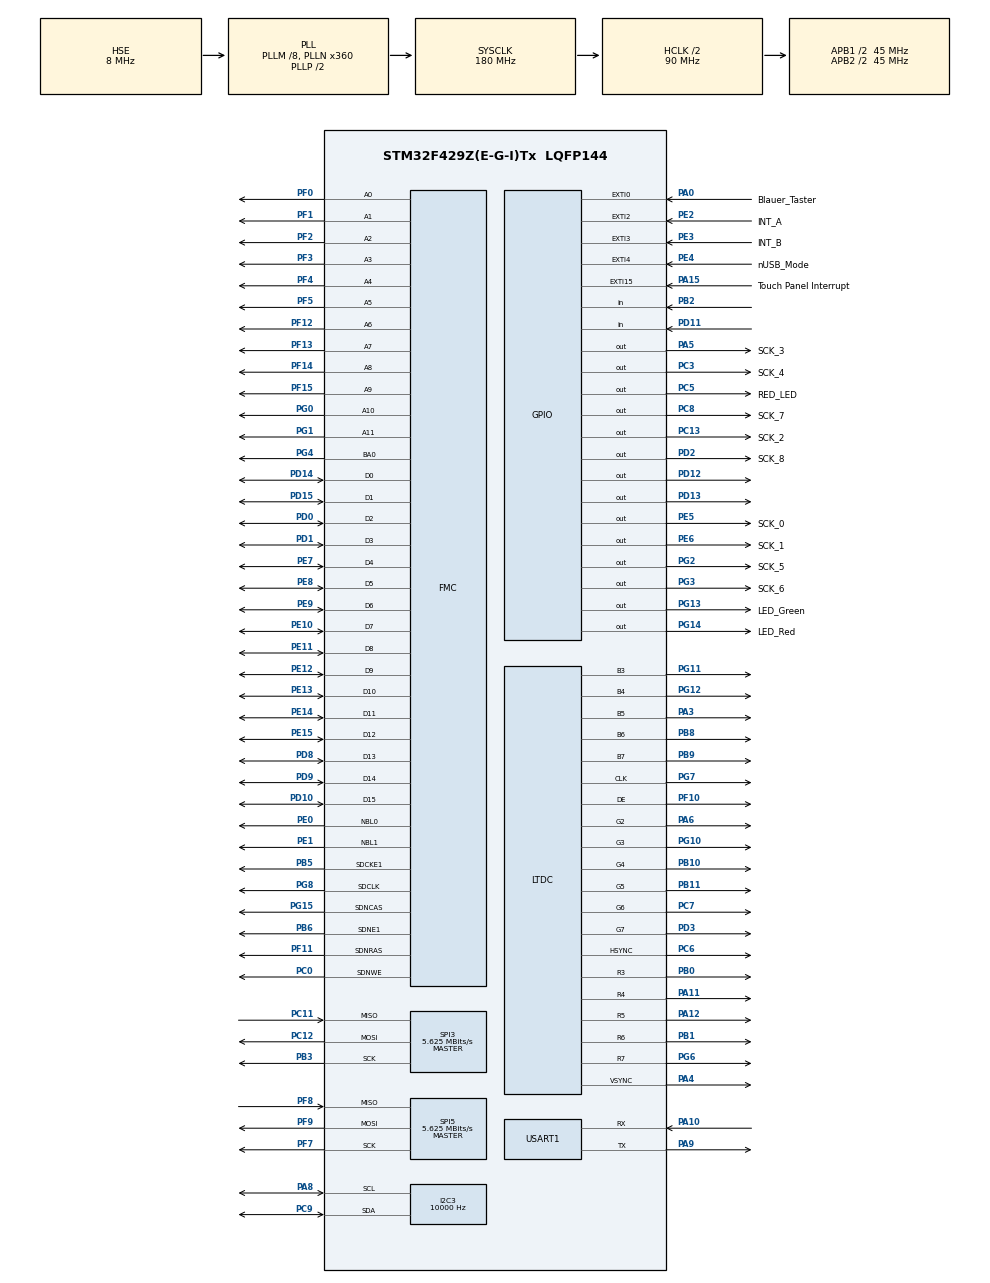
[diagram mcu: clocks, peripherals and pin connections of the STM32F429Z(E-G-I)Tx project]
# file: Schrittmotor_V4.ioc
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DMA2D.AlphaModeForeground=DMA2D_COMBINE_ALPHA
DMA2D.Mode=DMA2D_M2M
Dma.MEMTOMEM.2.Direction=DMA_MEMORY_TO_MEMORY
Dma.MEMTOMEM.2.FIFOMode=DMA_FIFOMODE_ENABLE
Dma.MEMTOMEM.2.FIFOThreshold=DMA_FIFO_THRESHOLD_FULL
Dma.MEMTOMEM.2.Instance=DMA2_Stream0
Dma.MEMTOMEM.2.MemBurst=DMA_MBURST_SINGLE
Dma.MEMTOMEM.2.MemDataAlignment=DMA_MDATAALIGN_BYTE
Dma.MEMTOMEM.2.MemInc=DMA_MINC_ENABLE
Dma.MEMTOMEM.2.Mode=DMA_NORMAL
Dma.MEMTOMEM.2.PeriphBurst=DMA_PBURST_SINGLE
Dma.MEMTOMEM.2.PeriphDataAlignment=DMA_PDATAALIGN_BYTE
Dma.MEMTOMEM.2.PeriphInc=DMA_PINC_ENABLE
Dma.MEMTOMEM.2.Priority=DMA_PRIORITY_LOW
Dma.Request0=USART1_RX
Dma.Request1=USART1_TX
Dma.Request2=MEMTOMEM
Dma.USART1_RX.0.Direction=DMA_PERIPH_TO_MEMORY
Dma.USART1_RX.0.FIFOMode=DMA_FIFOMODE_DISABLE
Dma.USART1_RX.0.Instance=DMA2_Stream2
Dma.USART1_RX.0.MemDataAlignment=DMA_MDATAALIGN_BYTE
Dma.USART1_RX.0.MemInc=DMA_MINC_ENABLE
Dma.USART1_RX.0.Mode=DMA_CIRCULAR
Dma.USART1_RX.0.PeriphDataAlignment=DMA_PDATAALIGN_BYTE
Dma.USART1_RX.0.PeriphInc=DMA_PINC_DISABLE
Dma.USART1_RX.0.Priority=DMA_PRIORITY_LOW
Dma.USART1_TX.1.Direction=DMA_MEMORY_TO_PERIPH
Dma.USART1_TX.1.FIFOMode=DMA_FIFOMODE_DISABLE
Dma.USART1_TX.1.Instance=DMA2_Stream7
Dma.USART1_TX.1.MemDataAlignment=DMA_MDATAALIGN_BYTE
Dma.USART1_TX.1.MemInc=DMA_MINC_ENABLE
Dma.USART1_TX.1.Mode=DMA_CIRCULAR
Dma.USART1_TX.1.PeriphDataAlignment=DMA_PDATAALIGN_BYTE
Dma.USART1_TX.1.PeriphInc=DMA_PINC_DISABLE
Dma.USART1_TX.1.Priority=DMA_PRIORITY_LOW
I2C3.ClockSpeed=10000
I2C3.I2C_Mode=I2C_Fast
LTDC.BlendingFactor1_L0=LTDC_BLENDING_FACTOR1_PAxCA
LTDC.BlendingFactor2_L0=LTDC_BLENDING_FACTOR2_PAxCA
LTDC.Layers=0
Mcu.Family=STM32F4
Mcu.Name=STM32F429Z(E-G-I)Tx
Mcu.Package=LQFP144
NVIC.DMA2_Stream2_IRQn=true\:0\:0\:false\:false\:true\:true
NVIC.DMA2_Stream7_IRQn=true\:0\:0\:false\:false\:true\:true
NVIC.EXTI0_IRQn=true\:4\:0\:true\:false\:true\:true
NVIC.EXTI15_10_IRQn=true\:3\:0\:true\:false\:true\:true
NVIC.EXTI2_IRQn=true\:2\:0\:true\:false\:true\:true
NVIC.EXTI3_IRQn=true\:5\:0\:true\:false\:true\:true
NVIC.EXTI4_IRQn=true\:5\:0\:true\:false\:true\:true
NVIC.PriorityGroup=NVIC_PRIORITYGROUP_4
NVIC.USART1_IRQn=true\:1\:0\:true\:false\:true\:true
PA0/WKUP.GPIO_Label=Blauer_Taster
PA0/WKUP.GPIO_ModeDefaultEXTI=GPIO_MODE_IT_RISING
PA0/WKUP.GPIO_PuPd=GPIO_NOPULL
PA0/WKUP.Signal=GPXTI0
PA10.GPIO_Mode=GPIO_MODE_AF_PP
PA10.GPIO_PuPd=GPIO_PULLUP
PA10.GPIO_Speed=GPIO_SPEED_FREQ_VERY_HIGH
PA10.Mode=Asynchronous
PA10.Signal=USART1_RX
PA11.GPIO_Mode=GPIO_MODE_AF_PP
PA11.GPIO_PuPd=GPIO_NOPULL
PA11.GPIO_Speed=GPIO_SPEED_FREQ_LOW
PA11.Mode=RGB565
PA11.Signal=LTDC_R4
PA12.GPIO_Mode=GPIO_MODE_AF_PP
PA12.GPIO_PuPd=GPIO_NOPULL
PA12.GPIO_Speed=GPIO_SPEED_FREQ_LOW
PA12.Mode=RGB565
PA12.Signal=LTDC_R5
PA13.Signal=SYS_JTMS-SWDIO
PA14.Signal=SYS_JTCK-SWCLK
PA15.GPIO_Label=Touch Panel Interrupt
PA15.Signal=GPXTI15
PA3.GPIO_Mode=GPIO_MODE_AF_PP
PA3.GPIO_PuPd=GPIO_NOPULL
PA3.GPIO_Speed=GPIO_SPEED_FREQ_LOW
PA3.Mode=RGB565
PA3.Signal=LTDC_B5
PA4.GPIO_Mode=GPIO_MODE_AF_PP
PA4.GPIO_PuPd=GPIO_NOPULL
PA4.GPIO_Speed=GPIO_SPEED_FREQ_LOW
PA4.Mode=RGB565
PA4.Signal=LTDC_VSYNC
PA5.GPIO_Label=SCK_3
PA5.Signal=GPIO_Output
PA6.GPIO_Mode=GPIO_MODE_AF_PP
PA6.GPIO_PuPd=GPIO_NOPULL
PA6.GPIO_Speed=GPIO_SPEED_FREQ_LOW
PA6.Mode=RGB565
PA6.Signal=LTDC_G2
PA8.GPIO_Mode=GPIO_MODE_AF_OD
PA8.GPIO_PuPd=GPIO_NOPULL
PA8.GPIO_PuPdOD=GPIO_PULLUP
PA8.GPIO_Speed=GPIO_SPEED_FREQ_VERY_HIGH
PA8.Mode=I2C
PA8.Signal=I2C3_SCL
PA9.GPIO_Mode=GPIO_MODE_AF_PP
PA9.GPIO_PuPd=GPIO_PULLUP
PA9.GPIO_Speed=GPIO_SPEED_FREQ_VERY_HIGH
PA9.Mode=Asynchronous
PA9.Signal=USART1_TX
PB0.GPIO_Mode=GPIO_MODE_AF_PP
PB0.GPIO_PuPd=GPIO_NOPULL
PB0.GPIO_Speed=GPIO_SPEED_FREQ_LOW
PB0.Mode=RGB565
PB0.Signal=LTDC_R3
PB1.GPIO_Mode=GPIO_MODE_AF_PP
PB1.GPIO_PuPd=GPIO_NOPULL
PB1.GPIO_Speed=GPIO_SPEED_FREQ_LOW
PB1.Mode=RGB565
PB1.Signal=LTDC_R6
PB10.GPIO_Mode=GPIO_MODE_AF_PP
PB10.GPIO_PuPd=GPIO_NOPULL
PB10.GPIO_Speed=GPIO_SPEED_FREQ_LOW
PB10.Mode=RGB565
PB10.Signal=LTDC_G4
PB11.GPIO_Mode=GPIO_MODE_AF_PP
PB11.GPIO_PuPd=GPIO_NOPULL
PB11.GPIO_Speed=GPIO_SPEED_FREQ_LOW
PB11.Mode=RGB565
PB11.Signal=LTDC_G5
PB12.GPIO_Mode=GPIO_MODE_AF_PP
PB12.GPIO_PuPd=GPIO_NOPULL
PB12.GPIO_Speed=GPIO_SPEED_FREQ_VERY_HIGH
PB12.Signal=USB_OTG_HS_ID
PB13.GPIO_Mode=GPIO_MODE_INPUT
PB13.GPIO_PuPd=GPIO_NOPULL
PB13.Signal=USB_OTG_HS_VBUS
PB14.GPIO_Mode=GPIO_MODE_AF_PP
PB14.GPIO_PuPd=GPIO_NOPULL
PB14.GPIO_Speed=GPIO_SPEED_FREQ_VERY_HIGH
PB14.Signal=USB_OTG_HS_DM
PB15.GPIO_Mode=GPIO_MODE_AF_PP
PB15.GPIO_PuPd=GPIO_NOPULL
PB15.GPIO_Speed=GPIO_SPEED_FREQ_VERY_HIGH
PB15.Signal=USB_OTG_HS_DP
PB2/BOOT1.GPIO_Mode=GPIO_MODE_INPUT
PB2/BOOT1.GPIO_PuPd=GPIO_NOPULL
PB2/BOOT1.Signal=GPIO_Input
PB3.GPIO_Mode=GPIO_MODE_AF_PP
PB3.GPIO_PuPd=GPIO_NOPULL
PB3.GPIO_Speed=GPIO_SPEED_FREQ_VERY_HIGH
PB3.Mode=Full_Duplex_Master
PB3.Signal=SPI3_SCK
PB5.GPIO_Mode=GPIO_MODE_AF_PP
PB5.GPIO_PuPd=GPIO_NOPULL
PB5.GPIO_Speed=GPIO_SPEED_FREQ_VERY_HIGH
PB5.GPIO_Speed_High_Default=GPIO_SPEED_FREQ_VERY_HIGH
PB5.Mode=SdramChipSelect2_1
PB5.Signal=FMC_SDCKE1
PB6.GPIO_Mode=GPIO_MODE_AF_PP
PB6.GPIO_PuPd=GPIO_NOPULL
PB6.GPIO_Speed=GPIO_SPEED_FREQ_VERY_HIGH
PB6.GPIO_Speed_High_Default=GPIO_SPEED_FREQ_VERY_HIGH
PB6.Mode=SdramChipSelect2_1
PB6.Signal=FMC_SDNE1
PB8.GPIO_Mode=GPIO_MODE_AF_PP
PB8.GPIO_PuPd=GPIO_NOPULL
PB8.GPIO_Speed=GPIO_SPEED_FREQ_LOW
PB8.Mode=RGB565
PB8.Signal=LTDC_B6
PB9.GPIO_Mode=GPIO_MODE_AF_PP
PB9.GPIO_PuPd=GPIO_NOPULL
PB9.GPIO_Speed=GPIO_SPEED_FREQ_LOW
PB9.Mode=RGB565
PB9.Signal=LTDC_B7
PC0.GPIO_Mode=GPIO_MODE_AF_PP
PC0.GPIO_PuPd=GPIO_NOPULL
PC0.GPIO_Speed=GPIO_SPEED_FREQ_VERY_HIGH
PC0.GPIO_Speed_High_Default=GPIO_SPEED_FREQ_VERY_HIGH
PC0.Signal=FMC_SDNWE
PC10.GPIO_Mode=GPIO_MODE_AF_PP
PC10.GPIO_PuPd=GPIO_NOPULL
PC10.GPIO_Speed=GPIO_SPEED_FREQ_LOW
PC10.Signal=LTDC_R2
PC11.GPIO_Mode=GPIO_MODE_AF_PP
PC11.GPIO_PuPd=GPIO_NOPULL
PC11.GPIO_Speed=GPIO_SPEED_FREQ_VERY_HIGH
PC11.Mode=Full_Duplex_Master
PC11.Signal=SPI3_MISO
PC12.GPIO_Mode=GPIO_MODE_AF_PP
PC12.GPIO_PuPd=GPIO_NOPULL
PC12.GPIO_Speed=GPIO_SPEED_FREQ_VERY_HIGH
PC12.Mode=Full_Duplex_Master
PC12.Signal=SPI3_MOSI
PC13.GPIO_Label=SCK_2
PC13.Signal=GPIO_Output
PC14/OSC32_IN.Signal=RCC_OSC32_IN
PC15/OSC32_OUT.Signal=RCC_OSC32_OUT
PC3.GPIO_Label=SCK_4
PC3.Signal=GPIO_Output
PC5.GPIO_Label=RED_LED
PC5.Signal=GPIO_Output
PC6.GPIO_Mode=GPIO_MODE_AF_PP
PC6.GPIO_PuPd=GPIO_NOPULL
PC6.GPIO_Speed=GPIO_SPEED_FREQ_LOW
PC6.Mode=RGB565
PC6.Signal=LTDC_HSYNC
PC7.GPIO_Mode=GPIO_MODE_AF_PP
PC7.GPIO_PuPd=GPIO_NOPULL
PC7.GPIO_Speed=GPIO_SPEED_FREQ_LOW
PC7.Mode=RGB565
PC7.Signal=LTDC_G6
PC8.GPIO_Label=SCK_7
PC8.Signal=GPIO_Output
PC9.GPIO_Mode=GPIO_MODE_AF_OD
PC9.GPIO_PuPd=GPIO_NOPULL
PC9.GPIO_PuPdOD=GPIO_PULLUP
PC9.GPIO_Speed=GPIO_SPEED_FREQ_VERY_HIGH
PC9.Mode=I2C
PC9.Signal=I2C3_SDA
PD0.GPIO_Mode=GPIO_MODE_AF_PP
PD0.GPIO_PuPd=GPIO_NOPULL
PD0.GPIO_Speed=GPIO_SPEED_FREQ_VERY_HIGH
PD0.GPIO_Speed_High_Default=GPIO_SPEED_FREQ_VERY_HIGH
PD0.Signal=FMC_D2_DA2
PD1.GPIO_Mode=GPIO_MODE_AF_PP
PD1.GPIO_PuPd=GPIO_NOPULL
PD1.GPIO_Speed=GPIO_SPEED_FREQ_VERY_HIGH
PD1.GPIO_Speed_High_Default=GPIO_SPEED_FREQ_VERY_HIGH
PD1.Signal=FMC_D3_DA3
PD10.GPIO_Mode=GPIO_MODE_AF_PP
PD10.GPIO_PuPd=GPIO_NOPULL
PD10.GPIO_Speed=GPIO_SPEED_FREQ_VERY_HIGH
PD10.GPIO_Speed_High_Default=GPIO_SPEED_FREQ_VERY_HIGH
PD10.Signal=FMC_D15_DA15
PD11.GPIO_Mode=GPIO_MODE_INPUT
PD11.GPIO_PuPd=GPIO_NOPULL
PD11.Signal=GPIO_Input
PD12.GPIO_Mode=GPIO_MODE_OUTPUT_PP
PD12.GPIO_ModeDefaultOutputPP=GPIO_MODE_OUTPUT_PP
PD12.GPIO_PuPd=GPIO_NOPULL
PD12.GPIO_Speed=GPIO_SPEED_FREQ_LOW
PD12.PinState=GPIO_PIN_RESET
PD12.Signal=GPIO_Output
PD13.GPIO_Mode=GPIO_MODE_OUTPUT_PP
PD13.GPIO_ModeDefaultOutputPP=GPIO_MODE_OUTPUT_PP
PD13.GPIO_PuPd=GPIO_NOPULL
PD13.GPIO_Speed=GPIO_SPEED_FREQ_LOW
PD13.PinState=GPIO_PIN_RESET
PD13.Signal=GPIO_Output
PD14.GPIO_Mode=GPIO_MODE_AF_PP
PD14.GPIO_PuPd=GPIO_NOPULL
PD14.GPIO_Speed=GPIO_SPEED_FREQ_VERY_HIGH
PD14.GPIO_Speed_High_Default=GPIO_SPEED_FREQ_VERY_HIGH
PD14.Signal=FMC_D0_DA0
PD15.GPIO_Mode=GPIO_MODE_AF_PP
PD15.GPIO_PuPd=GPIO_NOPULL
PD15.GPIO_Speed=GPIO_SPEED_FREQ_VERY_HIGH
PD15.GPIO_Speed_High_Default=GPIO_SPEED_FREQ_VERY_HIGH
PD15.Signal=FMC_D1_DA1
PD2.GPIO_Label=SCK_8
PD2.Signal=GPIO_Output
PD3.GPIO_Mode=GPIO_MODE_AF_PP
PD3.GPIO_PuPd=GPIO_NOPULL
PD3.GPIO_Speed=GPIO_SPEED_FREQ_LOW
PD3.Mode=RGB565
PD3.Signal=LTDC_G7
PD6.GPIO_Mode=GPIO_MODE_AF_PP
PD6.GPIO_PuPd=GPIO_NOPULL
PD6.GPIO_Speed=GPIO_SPEED_FREQ_LOW
PD6.Signal=LTDC_B2
PD8.GPIO_Mode=GPIO_MODE_AF_PP
PD8.GPIO_PuPd=GPIO_NOPULL
PD8.GPIO_Speed=GPIO_SPEED_FREQ_VERY_HIGH
PD8.GPIO_Speed_High_Default=GPIO_SPEED_FREQ_VERY_HIGH
PD8.Signal=FMC_D13_DA13
PD9.GPIO_Mode=GPIO_MODE_AF_PP
PD9.GPIO_PuPd=GPIO_NOPULL
PD9.GPIO_Speed=GPIO_SPEED_FREQ_VERY_HIGH
PD9.GPIO_Speed_High_Default=GPIO_SPEED_FREQ_VERY_HIGH
PD9.Signal=FMC_D14_DA14
PE0.GPIO_Mode=GPIO_MODE_AF_PP
PE0.GPIO_PuPd=GPIO_NOPULL
PE0.GPIO_Speed=GPIO_SPEED_FREQ_VERY_HIGH
PE0.GPIO_Speed_High_Default=GPIO_SPEED_FREQ_VERY_HIGH
PE0.Signal=FMC_NBL0
PE1.GPIO_Mode=GPIO_MODE_AF_PP
PE1.GPIO_PuPd=GPIO_NOPULL
PE1.GPIO_Speed=GPIO_SPEED_FREQ_VERY_HIGH
PE1.GPIO_Speed_High_Default=GPIO_SPEED_FREQ_VERY_HIGH
PE1.Signal=FMC_NBL1
PE10.GPIO_Mode=GPIO_MODE_AF_PP
PE10.GPIO_PuPd=GPIO_NOPULL
PE10.GPIO_Speed=GPIO_SPEED_FREQ_VERY_HIGH
PE10.GPIO_Speed_High_Default=GPIO_SPEED_FREQ_VERY_HIGH
PE10.Signal=FMC_D7_DA7
PE11.GPIO_Mode=GPIO_MODE_AF_PP
PE11.GPIO_PuPd=GPIO_NOPULL
PE11.GPIO_Speed=GPIO_SPEED_FREQ_VERY_HIGH
PE11.GPIO_Speed_High_Default=GPIO_SPEED_FREQ_VERY_HIGH
PE11.Signal=FMC_D8_DA8
PE12.GPIO_Mode=GPIO_MODE_AF_PP
PE12.GPIO_PuPd=GPIO_NOPULL
PE12.GPIO_Speed=GPIO_SPEED_FREQ_VERY_HIGH
PE12.GPIO_Speed_High_Default=GPIO_SPEED_FREQ_VERY_HIGH
PE12.Signal=FMC_D9_DA9
PE13.GPIO_Mode=GPIO_MODE_AF_PP
PE13.GPIO_PuPd=GPIO_NOPULL
PE13.GPIO_Speed=GPIO_SPEED_FREQ_VERY_HIGH
PE13.GPIO_Speed_High_Default=GPIO_SPEED_FREQ_VERY_HIGH
PE13.Signal=FMC_D10_DA10
PE14.GPIO_Mode=GPIO_MODE_AF_PP
PE14.GPIO_PuPd=GPIO_NOPULL
PE14.GPIO_Speed=GPIO_SPEED_FREQ_VERY_HIGH
PE14.GPIO_Speed_High_Default=GPIO_SPEED_FREQ_VERY_HIGH
PE14.Signal=FMC_D11_DA11
PE15.GPIO_Mode=GPIO_MODE_AF_PP
PE15.GPIO_PuPd=GPIO_NOPULL
PE15.GPIO_Speed=GPIO_SPEED_FREQ_VERY_HIGH
PE15.GPIO_Speed_High_Default=GPIO_SPEED_FREQ_VERY_HIGH
PE15.Signal=FMC_D12_DA12
PE2.GPIO_Label=INT_A
PE2.GPIO_ModeDefaultEXTI=GPIO_MODE_IT_RISING
PE2.GPIO_PuPd=GPIO_NOPULL
PE2.Signal=GPXTI2
PE3.GPIO_Label=INT_B
PE3.GPIO_ModeDefaultEXTI=GPIO_MODE_IT_RISING
PE3.GPIO_PuPd=GPIO_NOPULL
PE3.Signal=GPXTI3
PE4.GPIO_Label=nUSB_Mode
PE4.Signal=GPXTI4
PE5.GPIO_Label=SCK_0
PE5.Signal=GPIO_Output
PE6.GPIO_Label=SCK_1
PE6.Signal=GPIO_Output
PE7.GPIO_Mode=GPIO_MODE_AF_PP
PE7.GPIO_PuPd=GPIO_NOPULL
PE7.GPIO_Speed=GPIO_SPEED_FREQ_VERY_HIGH
PE7.GPIO_Speed_High_Default=GPIO_SPEED_FREQ_VERY_HIGH
PE7.Signal=FMC_D4_DA4
PE8.GPIO_Mode=GPIO_MODE_AF_PP
PE8.GPIO_PuPd=GPIO_NOPULL
PE8.GPIO_Speed=GPIO_SPEED_FREQ_VERY_HIGH
PE8.GPIO_Speed_High_Default=GPIO_SPEED_FREQ_VERY_HIGH
PE8.Signal=FMC_D5_DA5
PE9.GPIO_Mode=GPIO_MODE_AF_PP
PE9.GPIO_PuPd=GPIO_NOPULL
PE9.GPIO_Speed=GPIO_SPEED_FREQ_VERY_HIGH
PE9.GPIO_Speed_High_Default=GPIO_SPEED_FREQ_VERY_HIGH
PE9.Signal=FMC_D6_DA6
PF0.GPIO_Mode=GPIO_MODE_AF_PP
PF0.GPIO_PuPd=GPIO_NOPULL
PF0.GPIO_Speed=GPIO_SPEED_FREQ_VERY_HIGH
PF0.GPIO_Speed_High_Default=GPIO_SPEED_FREQ_VERY_HIGH
PF0.Signal=FMC_A0
PF1.GPIO_Mode=GPIO_MODE_AF_PP
PF1.GPIO_PuPd=GPIO_NOPULL
PF1.GPIO_Speed=GPIO_SPEED_FREQ_VERY_HIGH
PF1.GPIO_Speed_High_Default=GPIO_SPEED_FREQ_VERY_HIGH
PF1.Signal=FMC_A1
PF10.GPIO_Mode=GPIO_MODE_AF_PP
PF10.GPIO_PuPd=GPIO_NOPULL
PF10.GPIO_Speed=GPIO_SPEED_FREQ_LOW
PF10.Mode=RGB565
PF10.Signal=LTDC_DE
PF11.GPIO_Mode=GPIO_MODE_AF_PP
PF11.GPIO_PuPd=GPIO_NOPULL
PF11.GPIO_Speed=GPIO_SPEED_FREQ_VERY_HIGH
PF11.GPIO_Speed_High_Default=GPIO_SPEED_FREQ_VERY_HIGH
PF11.Signal=FMC_SDNRAS
PF12.GPIO_Mode=GPIO_MODE_AF_PP
PF12.GPIO_PuPd=GPIO_NOPULL
PF12.GPIO_Speed=GPIO_SPEED_FREQ_VERY_HIGH
PF12.GPIO_Speed_High_Default=GPIO_SPEED_FREQ_VERY_HIGH
PF12.Signal=FMC_A6
PF13.GPIO_Mode=GPIO_MODE_AF_PP
PF13.GPIO_PuPd=GPIO_NOPULL
PF13.GPIO_Speed=GPIO_SPEED_FREQ_VERY_HIGH
PF13.GPIO_Speed_High_Default=GPIO_SPEED_FREQ_VERY_HIGH
PF13.Signal=FMC_A7
PF14.GPIO_Mode=GPIO_MODE_AF_PP
PF14.GPIO_PuPd=GPIO_NOPULL
PF14.GPIO_Speed=GPIO_SPEED_FREQ_VERY_HIGH
PF14.GPIO_Speed_High_Default=GPIO_SPEED_FREQ_VERY_HIGH
PF14.Signal=FMC_A8
PF15.GPIO_Mode=GPIO_MODE_AF_PP
PF15.GPIO_PuPd=GPIO_NOPULL
PF15.GPIO_Speed=GPIO_SPEED_FREQ_VERY_HIGH
PF15.GPIO_Speed_High_Default=GPIO_SPEED_FREQ_VERY_HIGH
PF15.Signal=FMC_A9
PF2.GPIO_Mode=GPIO_MODE_AF_PP
PF2.GPIO_PuPd=GPIO_NOPULL
PF2.GPIO_Speed=GPIO_SPEED_FREQ_VERY_HIGH
PF2.GPIO_Speed_High_Default=GPIO_SPEED_FREQ_VERY_HIGH
PF2.Signal=FMC_A2
PF3.GPIO_Mode=GPIO_MODE_AF_PP
PF3.GPIO_PuPd=GPIO_NOPULL
PF3.GPIO_Speed=GPIO_SPEED_FREQ_VERY_HIGH
PF3.GPIO_Speed_High_Default=GPIO_SPEED_FREQ_VERY_HIGH
PF3.Signal=FMC_A3
PF4.GPIO_Mode=GPIO_MODE_AF_PP
PF4.GPIO_PuPd=GPIO_NOPULL
PF4.GPIO_Speed=GPIO_SPEED_FREQ_VERY_HIGH
PF4.GPIO_Speed_High_Default=GPIO_SPEED_FREQ_VERY_HIGH
PF4.Signal=FMC_A4
PF5.GPIO_Mode=GPIO_MODE_AF_PP
PF5.GPIO_PuPd=GPIO_NOPULL
PF5.GPIO_Speed=GPIO_SPEED_FREQ_VERY_HIGH
PF5.GPIO_Speed_High_Default=GPIO_SPEED_FREQ_VERY_HIGH
PF5.Signal=FMC_A5
PF7.GPIO_Mode=GPIO_MODE_AF_PP
PF7.GPIO_PuPd=GPIO_NOPULL
PF7.GPIO_Speed=GPIO_SPEED_FREQ_VERY_HIGH
PF7.Mode=Full_Duplex_Master
PF7.Signal=SPI5_SCK
PF8.GPIO_Mode=GPIO_MODE_AF_PP
PF8.GPIO_PuPd=GPIO_NOPULL
PF8.GPIO_Speed=GPIO_SPEED_FREQ_VERY_HIGH
PF8.Mode=Full_Duplex_Master
PF8.Signal=SPI5_MISO
PF9.GPIO_Mode=GPIO_MODE_AF_PP
PF9.GPIO_PuPd=GPIO_NOPULL
PF9.GPIO_Speed=GPIO_SPEED_FREQ_VERY_HIGH
PF9.Mode=Full_Duplex_Master
PF9.Signal=SPI5_MOSI
PG0.GPIO_Mode=GPIO_MODE_AF_PP
PG0.GPIO_PuPd=GPIO_NOPULL
PG0.GPIO_Speed=GPIO_SPEED_FREQ_VERY_HIGH
PG0.GPIO_Speed_High_Default=GPIO_SPEED_FREQ_VERY_HIGH
PG0.Signal=FMC_A10
PG1.GPIO_Mode=GPIO_MODE_AF_PP
PG1.GPIO_PuPd=GPIO_NOPULL
PG1.GPIO_Speed=GPIO_SPEED_FREQ_VERY_HIGH
PG1.GPIO_Speed_High_Default=GPIO_SPEED_FREQ_VERY_HIGH
PG1.Signal=FMC_A11
PG10.GPIO_Mode=GPIO_MODE_AF_PP
PG10.GPIO_PuPd=GPIO_NOPULL
PG10.GPIO_Speed=GPIO_SPEED_FREQ_LOW
PG10.Mode=RGB565
PG10.Signal=LTDC_G3
PG11.GPIO_Mode=GPIO_MODE_AF_PP
PG11.GPIO_PuPd=GPIO_NOPULL
PG11.GPIO_Speed=GPIO_SPEED_FREQ_LOW
PG11.Mode=RGB565
PG11.Signal=LTDC_B3
PG12.GPIO_Mode=GPIO_MODE_AF_PP
PG12.GPIO_PuPd=GPIO_NOPULL
PG12.GPIO_Speed=GPIO_SPEED_FREQ_LOW
PG12.Mode=RGB565
PG12.Signal=LTDC_B4
PG13.GPIO_Label=LED_Green
PG13.GPIO_Mode=GPIO_MODE_OUTPUT_PP
PG13.GPIO_ModeDefaultOutputPP=GPIO_MODE_OUTPUT_PP
PG13.GPIO_PuPd=GPIO_NOPULL
PG13.GPIO_Speed=GPIO_SPEED_FREQ_LOW
PG13.PinState=GPIO_PIN_RESET
PG13.Signal=GPIO_Output
PG14.GPIO_Label=LED_Red
PG14.GPIO_Mode=GPIO_MODE_OUTPUT_PP
PG14.GPIO_ModeDefaultOutputPP=GPIO_MODE_OUTPUT_PP
PG14.GPIO_PuPd=GPIO_NOPULL
PG14.GPIO_Speed=GPIO_SPEED_FREQ_LOW
PG14.PinState=GPIO_PIN_RESET
PG14.Signal=GPIO_Output
PG15.GPIO_Mode=GPIO_MODE_AF_PP
PG15.GPIO_PuPd=GPIO_NOPULL
PG15.GPIO_Speed=GPIO_SPEED_FREQ_VERY_HIGH
PG15.GPIO_Speed_High_Default=GPIO_SPEED_FREQ_VERY_HIGH
PG15.Signal=FMC_SDNCAS
PG2.GPIO_Label=SCK_5
PG2.Signal=GPIO_Output
PG3.GPIO_Label=SCK_6
PG3.Signal=GPIO_Output
PG4.GPIO_Mode=GPIO_MODE_AF_PP
PG4.GPIO_PuPd=GPIO_NOPULL
PG4.GPIO_Speed=GPIO_SPEED_FREQ_VERY_HIGH
PG4.GPIO_Speed_High_Default=GPIO_SPEED_FREQ_VERY_HIGH
PG4.Signal=FMC_A14_BA0
PG5.GPIO_Mode=GPIO_MODE_AF_PP
PG5.GPIO_PuPd=GPIO_NOPULL
PG5.GPIO_Speed=GPIO_SPEED_FREQ_VERY_HIGH
PG5.GPIO_Speed_High_Default=GPIO_SPEED_FREQ_VERY_HIGH
PG5.Signal=FMC_A15_BA1
PG6.GPIO_Mode=GPIO_MODE_AF_PP
PG6.GPIO_PuPd=GPIO_NOPULL
PG6.GPIO_Speed=GPIO_SPEED_FREQ_LOW
PG6.Mode=RGB565
PG6.Signal=LTDC_R7
PG7.GPIO_Mode=GPIO_MODE_AF_PP
PG7.GPIO_PuPd=GPIO_NOPULL
PG7.GPIO_Speed=GPIO_SPEED_FREQ_LOW
PG7.Mode=RGB565
PG7.Signal=LTDC_CLK
PG8.GPIO_Mode=GPIO_MODE_AF_PP
PG8.GPIO_PuPd=GPIO_NOPULL
PG8.GPIO_Speed=GPIO_SPEED_FREQ_VERY_HIGH
PG8.GPIO_Speed_High_Default=GPIO_SPEED_FREQ_VERY_HIGH
PG8.Signal=FMC_SDCLK
PH0/OSC_IN.Mode=HSE-External-Oscillator
PH0/OSC_IN.Signal=RCC_OSC_IN
PH1/OSC_OUT.Mode=HSE-External-Oscillator
PH1/OSC_OUT.Signal=RCC_OSC_OUT
ProjectManager.HeapSize=0x200
ProjectManager.StackSize=0x400
ProjectManager.TargetToolchain=SW4STM32
RCC.48MHZClocksFreq_Value=51428571.428571425
RCC.AHBCLKDivider=RCC_SYSCLK_DIV2
RCC.AHBFreq_Value=90000000
RCC.APB1CLKDivider=RCC_HCLK_DIV2
RCC.APB1Freq_Value=45000000
RCC.APB1TimFreq_Value=90000000
RCC.APB2CLKDivider=RCC_HCLK_DIV2
RCC.APB2Freq_Value=45000000
RCC.APB2TimFreq_Value=90000000
RCC.CortexFreq_Value=90000000
RCC.HCLKFreq_Value=90000000
RCC.HSE_VALUE=8000000
RCC.HSI_VALUE=16000000
RCC.LSE_VALUE=32768
RCC.PLLM=8
RCC.PLLN=360
RCC.PLLQ=7
RCC.PLLSAIN=192
RCC.PLLSAIR=4
RCC.PLLSourceVirtual=RCC_PLLSOURCE_HSE
RCC.SYSCLKFreq_VALUE=180000000
RCC.SYSCLKSource=RCC_SYSCLKSOURCE_PLLCLK
RCC.VCOOutputFreq_Value=360000000
SH.FMC_A0.0=FMC_A0,12b-sda1
SH.FMC_A1.0=FMC_A1,12b-sda1
SH.FMC_A10.0=FMC_A10,12b-sda1
SH.FMC_A11.0=FMC_A11,12b-sda1
SH.FMC_A14_BA0.0=FMC_BA0,TwoSdramBanks1
SH.FMC_A15_BA1.0=FMC_BA1
SH.FMC_A2.0=FMC_A2,12b-sda1
SH.FMC_A3.0=FMC_A3,12b-sda1
SH.FMC_A4.0=FMC_A4,12b-sda1
SH.FMC_A5.0=FMC_A5,12b-sda1
SH.FMC_A6.0=FMC_A6,12b-sda1
SH.FMC_A7.0=FMC_A7,12b-sda1
SH.FMC_A8.0=FMC_A8,12b-sda1
SH.FMC_A9.0=FMC_A9,12b-sda1
SH.FMC_D0_DA0.0=FMC_D0,sd-16b-d1
SH.FMC_D10_DA10.0=FMC_D10,sd-16b-d1
SH.FMC_D11_DA11.0=FMC_D11,sd-16b-d1
SH.FMC_D12_DA12.0=FMC_D12,sd-16b-d1
SH.FMC_D13_DA13.0=FMC_D13,sd-16b-d1
SH.FMC_D14_DA14.0=FMC_D14,sd-16b-d1
SH.FMC_D15_DA15.0=FMC_D15,sd-16b-d1
SH.FMC_D1_DA1.0=FMC_D1,sd-16b-d1
SH.FMC_D2_DA2.0=FMC_D2,sd-16b-d1
SH.FMC_D3_DA3.0=FMC_D3,sd-16b-d1
SH.FMC_D4_DA4.0=FMC_D4,sd-16b-d1
SH.FMC_D5_DA5.0=FMC_D5,sd-16b-d1
SH.FMC_D6_DA6.0=FMC_D6,sd-16b-d1
SH.FMC_D7_DA7.0=FMC_D7,sd-16b-d1
SH.FMC_D8_DA8.0=FMC_D8,sd-16b-d1
SH.FMC_D9_DA9.0=FMC_D9,sd-16b-d1
SH.FMC_NBL0.0=FMC_NBL0,Sd2ByteEnable1
SH.FMC_NBL1.0=FMC_NBL1,Sd2ByteEnable1
SH.FMC_SDCLK.0=FMC_SDCLK,12b-sda1
SH.FMC_SDNCAS.0=FMC_SDNCAS,12b-sda1
SH.FMC_SDNRAS.0=FMC_SDNRAS,12b-sda1
SH.FMC_SDNWE.0=FMC_SDNWE,12b-sda1
SPI3.BaudRatePrescaler=SPI_BAUDRATEPRESCALER_8
SPI3.CalculateBaudRate=5.625 MBits/s
SPI3.Direction=SPI_DIRECTION_2LINES
SPI3.Mode=SPI_MODE_MASTER
SPI3.VirtualType=VM_MASTER
SPI5.BaudRatePrescaler=SPI_BAUDRATEPRESCALER_8
SPI5.CRCCalculation=SPI_CRCCALCULATION_DISABLE
SPI5.CalculateBaudRate=5.625 MBits/s
SPI5.Direction=SPI_DIRECTION_2LINES
SPI5.Mode=SPI_MODE_MASTER
SPI5.VirtualType=VM_MASTER
USART1.VirtualMode=VM_ASYNC
VP_DMA2D_VS_DMA2D.Mode=DMA2D_Activate
board=STM32F429I-DISC1

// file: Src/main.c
/**
 ******************************************************************************
 * File Name          : main.c
 * Description        : Main program body
 ******************************************************************************
 ** This notice applies to any and all portions of this file
 * that are not between comment pairs USER CODE BEGIN and
 * USER CODE END. Other portions of this file, whether
 * inserted by the user or by software development tools
 * are owned by their respective copyright owners.
 *
 * COPYRIGHT(c) 2017 STMicroelectronics
 *
 * Redistribution and use in source and binary forms, with or without
 *modification,
 * are permitted provided that the following conditions are met:
 *   1. Redistributions of source code must retain the above copyright notice,
 *      this list of conditions and the following disclaimer.
 *   2. Redistributions in binary form must reproduce the above copyright
 *notice,
 *      this list of conditions and the following disclaimer in the
 *documentation
 *      and/or other materials provided with the distribution.
 *   3. Neither the name of STMicroelectronics nor the names of its contributors
 *      may be used to endorse or promote products derived from this software
 *      without specific prior written permission.
 *
 * THIS SOFTWARE IS PROVIDED BY THE COPYRIGHT HOLDERS AND CONTRIBUTORS "AS IS"
 * AND ANY EXPRESS OR IMPLIED WARRANTIES, INCLUDING, BUT NOT LIMITED TO, THE
 * IMPLIED WARRANTIES OF MERCHANTABILITY AND FITNESS FOR A PARTICULAR PURPOSE
 *ARE
 * DISCLAIMED. IN NO EVENT SHALL THE COPYRIGHT HOLDER OR CONTRIBUTORS BE LIABLE
 * FOR ANY DIRECT, INDIRECT, INCIDENTAL, SPECIAL, EXEMPLARY, OR CONSEQUENTIAL
 * DAMAGES (INCLUDING, BUT NOT LIMITED TO, PROCUREMENT OF SUBSTITUTE GOODS OR
 * SERVICES; LOSS OF USE, DATA, OR PROFITS; OR BUSINESS INTERRUPTION) HOWEVER
 * CAUSED AND ON ANY THEORY OF LIABILITY, WHETHER IN CONTRACT, STRICT LIABILITY,
 * OR TORT (INCLUDING NEGLIGENCE OR OTHERWISE) ARISING IN ANY WAY OUT OF THE USE
 * OF THIS SOFTWARE, EVEN IF ADVISED OF THE POSSIBILITY OF SUCH DAMAGE.
 *
 ******************************************************************************
 */
#include "main.h"
#include "stm32f4xx_hal.h"

/* USER CODE BEGIN Includes */
#include "at_io_expander.h"
#include "at_lcd.h"
#include "at_schrittmotor.h"
#include "at_uart.h"

#include "tm_stm32_lcd.h"
#include "tm_stm32_spi.h"
#include "tm_stm32_usart.h"
#include "tm_stm32f4_stmpe811.h"

#include "dspin.h"
#include "dspin_config.h"
/* USER CODE END Includes */

DMA2D_HandleTypeDef hdma2d;

I2C_HandleTypeDef hi2c3;

LTDC_HandleTypeDef hltdc;

SPI_HandleTypeDef hspi3;
SPI_HandleTypeDef hspi5;

UART_HandleTypeDef huart1;
DMA_HandleTypeDef hdma_usart1_rx;
DMA_HandleTypeDef hdma_usart1_tx;

DMA_HandleTypeDef hdma_memtomem_dma2_stream0;
SDRAM_HandleTypeDef hsdram1;

/* USER CODE BEGIN PV */
/* Private variables ---------------------------------------------------------*/
// TM_STMPE811_t LCD_Config;
TM_STMPE811_t LCD_Config;

// dSPIN_RegsStruct_TypeDef dSPIN_RegsStruct;
/*
 * Globale Variablen
 * Anschluss:
 *    Diese Variable muss leider global sein, weil sie in der Bibliothek von
 *    TM in einer Unterfunktion aufgerufen wird.
 *    Ich m�sste allen Funktionen diesen Parameter �bergeben und das ist eine
 *    Heidenarbeit
 *    Sie wird nur von der UART Funktion  geschrieben
 *    alle anderen lesen
 *
 * INIT_DONE:
 *    Wird verwendet damit Interrupts nicht bevor der Initialisierungs
 *    Prozess abgeschlossen ist ausgeführt werden
 */
uint8_t anschluss = 0;
uint8_t aktive_ports = 0;
uint8_t serie[9] = {0, 0, 0, 0, 0, 0, 0, 0, 0};

uint8_t INIT_DONE = FALSE;

/* Diese hier werden noch als lokale
 * Variablen definiert
 */
uint8_t aktuelle_seite = 0;
uint8_t aktuelle_taste = 0;

/* UART Buffer für Ein- und Ausgabe */
char UART1_Data = 0;
/* USER CODE END PV */

void SystemClock_Config(void);
static void MX_GPIO_Init(void);
static void MX_DMA_Init(void);
static void MX_SPI3_Init(void);
static void MX_USART1_UART_Init(void);
static void MX_DMA2D_Init(void);
static void MX_FMC_Init(void);
static void MX_SPI5_Init(void);
static void MX_LTDC_Init(void);
static void MX_I2C3_Init(void);

/* USER CODE BEGIN PFP */
/* Private function prototypes -----------------------------------------------*/

/* USER CODE END PFP */

int main(void) {
   /* USER CODE BEGIN 1 */
   //__HAL_UART_ENABLE_IT(&huart1, UART_IT_RXNE);
   /* USER CODE END 1 */

   /* MCU
    * Configuration----------------------------------------------------------*/

   /* Reset of all peripherals, Initializes the Flash interface and the Systick.
    */
   HAL_Init();

   /* Configure the system clock */
   SystemClock_Config();

   /* Initialize all configured peripherals */
   MX_GPIO_Init();
   MX_DMA_Init();
   MX_SPI3_Init();
   MX_USART1_UART_Init();
   MX_DMA2D_Init();
   MX_FMC_Init();
   MX_SPI5_Init();
   MX_LTDC_Init();
   MX_I2C3_Init();

   /* USER CODE BEGIN 2 */

   /*
    * Setze alle CS Signale auf Inaktiv
    * Könnte man auch mit Enumeration lösen...
    * Hier aber wurst
    */
   Expander_CS_INAKTIV;
   Anschluss_1_CS_INAKTIV;
   Anschluss_2_CS_INAKTIV;
   Anschluss_3_CS_INAKTIV;
   Anschluss_4_CS_INAKTIV;
   Anschluss_5_CS_INAKTIV;
   Anschluss_6_CS_INAKTIV;
   Anschluss_7_CS_INAKTIV;
   Anschluss_8_CS_INAKTIV;

   /*
    * Initialisierung der einzelen Module
    */
   TM_SPI_Init(EXPANDER_SPI, EXPANDER_SPI_PINS);
   HAL_Delay(100);
   at_lcd_init(&LCD_Config);
   at_lcd_page_0();
   HAL_Delay(5000);

   TM_LCD_Init();
   TM_LCD_SetXY(0, 0);
   TM_LCD_SetFont(&TM_Font_11x18);

   LCD_INFO("Initialisierung");
   HAL_Delay(1000);
   aktive_ports = at_schrittmotor_init();
   HAL_Delay(100);
   at_expander_init();
   HAL_Delay(100);
   LCD_INFO("abgeschlossen");
   HAL_Delay(1000);
   LCD_INFO("aktive Module")
   LCD_INFO(BYTE_TO_BINARY_PATTERN8, BYTE_TO_BINARY8(aktive_ports));
   HAL_Delay(3000);
   TM_LCD_Init();

   /* Starte HAL UART Interrupt */
   HAL_UART_Receive_IT(&huart1, &UART1_Data, sizeof(UART1_Data));

   INIT_DONE = TRUE;
   /*
    * Die HAL_Delay Funktion taucht im Quellcode leider immer wieder auf.
    * Da viele Abläufe nur mit einer gewissen Verzögerung funktionieren,
    * muss die Funktion drin bleiben. Eine bessere Lösung ist mir noch nicht
    * eingefallen.
    * Laut stm32f4xx_hal.c benutzt HAL_Delay die Systick Funktion.
    */

   while (1) {
   }
}

/*
 * System Clock Configuration
 */
void SystemClock_Config(void) {
   RCC_OscInitTypeDef RCC_OscInitStruct;
   RCC_ClkInitTypeDef RCC_ClkInitStruct;
   RCC_PeriphCLKInitTypeDef PeriphClkInitStruct;

   /*
    *Configure the main internal regulator output voltage
    */
   __HAL_RCC_PWR_CLK_ENABLE();

   __HAL_PWR_VOLTAGESCALING_CONFIG(PWR_REGULATOR_VOLTAGE_SCALE3);

   /*
    *Initializes the CPU, AHB and APB busses clocks
    */
   RCC_OscInitStruct.OscillatorType = RCC_OSCILLATORTYPE_HSE;
   RCC_OscInitStruct.HSEState = RCC_HSE_ON;
   RCC_OscInitStruct.PLL.PLLState = RCC_PLL_ON;
   RCC_OscInitStruct.PLL.PLLSource = RCC_PLLSOURCE_HSE;
   RCC_OscInitStruct.PLL.PLLM = 8;
   RCC_OscInitStruct.PLL.PLLN = 360;
   RCC_OscInitStruct.PLL.PLLP = RCC_PLLP_DIV2;
   RCC_OscInitStruct.PLL.PLLQ = 7;
   if (HAL_RCC_OscConfig(&RCC_OscInitStruct) != HAL_OK) {
      _Error_Handler(__FILE__, __LINE__);
   }

   /*
    *Activate the Over-Drive mode
    */
   if (HAL_PWREx_EnableOverDrive() != HAL_OK) {
      _Error_Handler(__FILE__, __LINE__);
   }

   /*
    *Initializes the CPU, AHB and APB busses clocks
    */
   RCC_ClkInitStruct.ClockType = RCC_CLOCKTYPE_HCLK | RCC_CLOCKTYPE_SYSCLK |
                                 RCC_CLOCKTYPE_PCLK1 | RCC_CLOCKTYPE_PCLK2;
   RCC_ClkInitStruct.SYSCLKSource = RCC_SYSCLKSOURCE_PLLCLK;
   RCC_ClkInitStruct.AHBCLKDivider = RCC_SYSCLK_DIV2;
   RCC_ClkInitStruct.APB1CLKDivider = RCC_HCLK_DIV2;
   RCC_ClkInitStruct.APB2CLKDivider = RCC_HCLK_DIV2;

   if (HAL_RCC_ClockConfig(&RCC_ClkInitStruct, FLASH_LATENCY_2) != HAL_OK) {
      _Error_Handler(__FILE__, __LINE__);
   }

   PeriphClkInitStruct.PeriphClockSelection = RCC_PERIPHCLK_LTDC;
   PeriphClkInitStruct.PLLSAI.PLLSAIN = 192;
   PeriphClkInitStruct.PLLSAI.PLLSAIR = 4;
   PeriphClkInitStruct.PLLSAIDivR = RCC_PLLSAIDIVR_2;
   if (HAL_RCCEx_PeriphCLKConfig(&PeriphClkInitStruct) != HAL_OK) {
      _Error_Handler(__FILE__, __LINE__);
   }

   /*
    *Configure the Systick interrupt time
    */
   HAL_SYSTICK_Config(HAL_RCC_GetHCLKFreq() / 1000);

   /*
    *Configure the Systick
    */
   HAL_SYSTICK_CLKSourceConfig(SYSTICK_CLKSOURCE_HCLK);

   /* SysTick_IRQn interrupt configuration */
   HAL_NVIC_SetPriority(SysTick_IRQn, 0, 0);
}

/* DMA2D init function */
static void MX_DMA2D_Init(void) {
   hdma2d.Instance = DMA2D;
   hdma2d.Init.Mode = DMA2D_M2M;
   hdma2d.Init.ColorMode = DMA2D_OUTPUT_ARGB8888;
   hdma2d.Init.OutputOffset = 0;
   hdma2d.LayerCfg[1].InputOffset = 0;
   hdma2d.LayerCfg[1].InputColorMode = DMA2D_INPUT_ARGB8888;
   hdma2d.LayerCfg[1].AlphaMode = DMA2D_COMBINE_ALPHA;
   hdma2d.LayerCfg[1].InputAlpha = 0;
   if (HAL_DMA2D_Init(&hdma2d) != HAL_OK) {
      _Error_Handler(__FILE__, __LINE__);
   }

   if (HAL_DMA2D_ConfigLayer(&hdma2d, 1) != HAL_OK) {
      _Error_Handler(__FILE__, __LINE__);
   }
}

/* I2C3 init function */
static void MX_I2C3_Init(void) {
   hi2c3.Instance = I2C3;
   hi2c3.Init.ClockSpeed = 10000;
   hi2c3.Init.DutyCycle = I2C_DUTYCYCLE_2;
   hi2c3.Init.OwnAddress1 = 0;
   hi2c3.Init.AddressingMode = I2C_ADDRESSINGMODE_7BIT;
   hi2c3.Init.DualAddressMode = I2C_DUALADDRESS_DISABLE;
   hi2c3.Init.OwnAddress2 = 0;
   hi2c3.Init.GeneralCallMode = I2C_GENERALCALL_DISABLE;
   hi2c3.Init.NoStretchMode = I2C_NOSTRETCH_DISABLE;
   if (HAL_I2C_Init(&hi2c3) != HAL_OK) {
      _Error_Handler(__FILE__, __LINE__);
   }
}

/* LTDC init function */
static void MX_LTDC_Init(void) {
   LTDC_LayerCfgTypeDef pLayerCfg;

   hltdc.Instance = LTDC;
   hltdc.Init.HSPolarity = LTDC_HSPOLARITY_AL;
   hltdc.Init.VSPolarity = LTDC_VSPOLARITY_AL;
   hltdc.Init.DEPolarity = LTDC_DEPOLARITY_AL;
   hltdc.Init.PCPolarity = LTDC_PCPOLARITY_IPC;
   hltdc.Init.HorizontalSync = 7;
   hltdc.Init.VerticalSync = 3;
   hltdc.Init.AccumulatedHBP = 14;
   hltdc.Init.AccumulatedVBP = 5;
   hltdc.Init.AccumulatedActiveW = 654;
   hltdc.Init.AccumulatedActiveH = 485;
   hltdc.Init.TotalWidth = 660;
   hltdc.Init.TotalHeigh = 487;
   hltdc.Init.Backcolor.Blue = 0;
   hltdc.Init.Backcolor.Green = 0;
   hltdc.Init.Backcolor.Red = 0;
   if (HAL_LTDC_Init(&hltdc) != HAL_OK) {
      _Error_Handler(__FILE__, __LINE__);
   }

   pLayerCfg.WindowX0 = 0;
   pLayerCfg.WindowX1 = 0;
   pLayerCfg.WindowY0 = 0;
   pLayerCfg.WindowY1 = 0;
   pLayerCfg.PixelFormat = LTDC_PIXEL_FORMAT_ARGB8888;
   pLayerCfg.Alpha = 0;
   pLayerCfg.Alpha0 = 0;
   pLayerCfg.BlendingFactor1 = LTDC_BLENDING_FACTOR1_PAxCA;
   pLayerCfg.BlendingFactor2 = LTDC_BLENDING_FACTOR2_PAxCA;
   pLayerCfg.FBStartAdress = 0;
   pLayerCfg.ImageWidth = 0;
   pLayerCfg.ImageHeight = 0;
   pLayerCfg.Backcolor.Blue = 0;
   pLayerCfg.Backcolor.Green = 0;
   pLayerCfg.Backcolor.Red = 0;
   if (HAL_LTDC_ConfigLayer(&hltdc, &pLayerCfg, 0) != HAL_OK) {
      _Error_Handler(__FILE__, __LINE__);
   }
}

/* SPI3 init function */
static void MX_SPI3_Init(void) {
   /* SPI3 parameter configuration*/
   hspi3.Instance = SPI3;
   hspi3.Init.Mode = SPI_MODE_MASTER;
   hspi3.Init.Direction = SPI_DIRECTION_2LINES;
   hspi3.Init.DataSize = SPI_DATASIZE_8BIT;
   hspi3.Init.CLKPolarity = SPI_POLARITY_LOW;
   hspi3.Init.CLKPhase = SPI_PHASE_1EDGE;
   hspi3.Init.NSS = SPI_NSS_SOFT;
   hspi3.Init.BaudRatePrescaler = SPI_BAUDRATEPRESCALER_8;
   hspi3.Init.FirstBit = SPI_FIRSTBIT_MSB;
   hspi3.Init.TIMode = SPI_TIMODE_DISABLE;
   hspi3.Init.CRCCalculation = SPI_CRCCALCULATION_DISABLE;
   hspi3.Init.CRCPolynomial = 10;
   if (HAL_SPI_Init(&hspi3) != HAL_OK) {
      _Error_Handler(__FILE__, __LINE__);
   }
}

/* SPI5 init function */
static void MX_SPI5_Init(void) {
   /* SPI5 parameter configuration*/
   hspi5.Instance = SPI5;
   hspi5.Init.Mode = SPI_MODE_MASTER;
   hspi5.Init.Direction = SPI_DIRECTION_2LINES;
   hspi5.Init.DataSize = SPI_DATASIZE_8BIT;
   hspi5.Init.CLKPolarity = SPI_POLARITY_LOW;
   hspi5.Init.CLKPhase = SPI_PHASE_1EDGE;
   hspi5.Init.NSS = SPI_NSS_SOFT;
   hspi5.Init.BaudRatePrescaler = SPI_BAUDRATEPRESCALER_8;
   hspi5.Init.FirstBit = SPI_FIRSTBIT_MSB;
   hspi5.Init.TIMode = SPI_TIMODE_DISABLE;
   hspi5.Init.CRCCalculation = SPI_CRCCALCULATION_DISABLE;
   hspi5.Init.CRCPolynomial = 10;
   if (HAL_SPI_Init(&hspi5) != HAL_OK) {
      _Error_Handler(__FILE__, __LINE__);
   }
}

/* USART1 init function */
static void MX_USART1_UART_Init(void) {
   huart1.Instance = USART1;
   huart1.Init.BaudRate = 115200;
   huart1.Init.WordLength = UART_WORDLENGTH_8B;
   huart1.Init.StopBits = UART_STOPBITS_1;
   huart1.Init.Parity = UART_PARITY_NONE;
   huart1.Init.Mode = UART_MODE_TX_RX;
   huart1.Init.HwFlowCtl = UART_HWCONTROL_NONE;
   huart1.Init.OverSampling = UART_OVERSAMPLING_16;
   if (HAL_UART_Init(&huart1) != HAL_OK) {
      _Error_Handler(__FILE__, __LINE__);
   }
}

/*
 * Enable DMA controller clock
 * Configure DMA for memory to memory transfers
 * hdma_memtomem_dma2_stream0
 */
static void MX_DMA_Init(void) {
   /* DMA controller clock enable */
   __HAL_RCC_DMA2_CLK_ENABLE();

   /* Configure DMA request hdma_memtomem_dma2_stream0 on DMA2_Stream0 */
   hdma_memtomem_dma2_stream0.Instance = DMA2_Stream0;
   hdma_memtomem_dma2_stream0.Init.Channel = DMA_CHANNEL_0;
   hdma_memtomem_dma2_stream0.Init.Direction = DMA_MEMORY_TO_MEMORY;
   hdma_memtomem_dma2_stream0.Init.PeriphInc = DMA_PINC_ENABLE;
   hdma_memtomem_dma2_stream0.Init.MemInc = DMA_MINC_ENABLE;
   hdma_memtomem_dma2_stream0.Init.PeriphDataAlignment = DMA_PDATAALIGN_BYTE;
   hdma_memtomem_dma2_stream0.Init.MemDataAlignment = DMA_MDATAALIGN_BYTE;
   hdma_memtomem_dma2_stream0.Init.Mode = DMA_NORMAL;
   hdma_memtomem_dma2_stream0.Init.Priority = DMA_PRIORITY_LOW;
   hdma_memtomem_dma2_stream0.Init.FIFOMode = DMA_FIFOMODE_ENABLE;
   hdma_memtomem_dma2_stream0.Init.FIFOThreshold = DMA_FIFO_THRESHOLD_FULL;
   hdma_memtomem_dma2_stream0.Init.MemBurst = DMA_MBURST_SINGLE;
   hdma_memtomem_dma2_stream0.Init.PeriphBurst = DMA_PBURST_SINGLE;
   if (HAL_DMA_Init(&hdma_memtomem_dma2_stream0) != HAL_OK) {
      _Error_Handler(__FILE__, __LINE__);
   }

   /* DMA interrupt init */
   /* DMA2_Stream2_IRQn interrupt configuration */
   HAL_NVIC_SetPriority(DMA2_Stream2_IRQn, 0, 0);
   HAL_NVIC_EnableIRQ(DMA2_Stream2_IRQn);
   /* DMA2_Stream7_IRQn interrupt configuration */
   HAL_NVIC_SetPriority(DMA2_Stream7_IRQn, 0, 0);
   HAL_NVIC_EnableIRQ(DMA2_Stream7_IRQn);
}
/* FMC initialization function */
static void MX_FMC_Init(void) {
   FMC_SDRAM_TimingTypeDef SdramTiming;

   /*
    * Perform the SDRAM1 memory initialization sequence
    */
   hsdram1.Instance = FMC_SDRAM_DEVICE;
   /* hsdram1.Init */
   hsdram1.Init.SDBank = FMC_SDRAM_BANK2;
   hsdram1.Init.ColumnBitsNumber = FMC_SDRAM_COLUMN_BITS_NUM_8;
   hsdram1.Init.RowBitsNumber = FMC_SDRAM_ROW_BITS_NUM_12;
   hsdram1.Init.MemoryDataWidth = FMC_SDRAM_MEM_BUS_WIDTH_16;
   hsdram1.Init.InternalBankNumber = FMC_SDRAM_INTERN_BANKS_NUM_2;
   hsdram1.Init.CASLatency = FMC_SDRAM_CAS_LATENCY_1;
   hsdram1.Init.WriteProtection = FMC_SDRAM_WRITE_PROTECTION_DISABLE;
   hsdram1.Init.SDClockPeriod = FMC_SDRAM_CLOCK_DISABLE;
   hsdram1.Init.ReadBurst = FMC_SDRAM_RBURST_DISABLE;
   hsdram1.Init.ReadPipeDelay = FMC_SDRAM_RPIPE_DELAY_0;
   /* SdramTiming */
   SdramTiming.LoadToActiveDelay = 16;
   SdramTiming.ExitSelfRefreshDelay = 16;
   SdramTiming.SelfRefreshTime = 16;
   SdramTiming.RowCycleDelay = 16;
   SdramTiming.WriteRecoveryTime = 16;
   SdramTiming.RPDelay = 16;
   SdramTiming.RCDDelay = 16;

   if (HAL_SDRAM_Init(&hsdram1, &SdramTiming) != HAL_OK) {
      _Error_Handler(__FILE__, __LINE__);
   }
}

/*
 * Configure pins as
 * Analog
 * Input
 * Output
 * EVENT_OUT
 * EXTI
 PB12   ------> USB_OTG_HS_ID
 PB13   ------> USB_OTG_HS_VBUS
 PB14   ------> USB_OTG_HS_DM
 PB15   ------> USB_OTG_HS_DP
 */
static void MX_GPIO_Init(void) {
   GPIO_InitTypeDef GPIO_InitStruct;

   /* GPIO Ports Clock Enable */
   __HAL_RCC_GPIOE_CLK_ENABLE();
   __HAL_RCC_GPIOC_CLK_ENABLE();
   __HAL_RCC_GPIOF_CLK_ENABLE();
   __HAL_RCC_GPIOH_CLK_ENABLE();
   __HAL_RCC_GPIOA_CLK_ENABLE();
   __HAL_RCC_GPIOB_CLK_ENABLE();
   __HAL_RCC_GPIOG_CLK_ENABLE();
   __HAL_RCC_GPIOD_CLK_ENABLE();

   /*Configure GPIO pin Output Level */
   HAL_GPIO_WritePin(GPIOE, SCK_0_Pin | SCK_1_Pin, GPIO_PIN_RESET);

   /*Configure GPIO pin Output Level */
   HAL_GPIO_WritePin(GPIOC, SCK_2_Pin | SCK_4_Pin | RED_LED_Pin | SCK_7_Pin,
                     GPIO_PIN_RESET);

   /*Configure GPIO pin Output Level */
   HAL_GPIO_WritePin(SCK_3_GPIO_Port, SCK_3_Pin, GPIO_PIN_RESET);

   /*Configure GPIO pin Output Level */
   HAL_GPIO_WritePin(GPIOD, GPIO_PIN_12 | GPIO_PIN_13 | SCK_8_Pin,
                     GPIO_PIN_RESET);

   /*Configure GPIO pin Output Level */
   HAL_GPIO_WritePin(GPIOG, SCK_5_Pin | SCK_6_Pin | LED_Green_Pin | LED_Red_Pin,
                     GPIO_PIN_RESET);

   /*Configure GPIO pins : INT_A_Pin INT_B_Pin nUSB_Mode_Pin */
   GPIO_InitStruct.Pin = INT_A_Pin | INT_B_Pin | nUSB_Mode_Pin;
   GPIO_InitStruct.Mode = GPIO_MODE_IT_RISING;
   GPIO_InitStruct.Pull = GPIO_NOPULL;
   HAL_GPIO_Init(GPIOE, &GPIO_InitStruct);

   /*Configure GPIO pins : SCK_0_Pin SCK_1_Pin */
   GPIO_InitStruct.Pin = SCK_0_Pin | SCK_1_Pin;
   GPIO_InitStruct.Mode = GPIO_MODE_OUTPUT_PP;
   GPIO_InitStruct.Pull = GPIO_NOPULL;
   GPIO_InitStruct.Speed = GPIO_SPEED_FREQ_LOW;
   HAL_GPIO_Init(GPIOE, &GPIO_InitStruct);

   /*Configure GPIO pins : SCK_2_Pin SCK_4_Pin RED_LED_Pin SCK_7_Pin */
   GPIO_InitStruct.Pin = SCK_2_Pin | SCK_4_Pin | RED_LED_Pin | SCK_7_Pin;
   GPIO_InitStruct.Mode = GPIO_MODE_OUTPUT_PP;
   GPIO_InitStruct.Pull = GPIO_NOPULL;
   GPIO_InitStruct.Speed = GPIO_SPEED_FREQ_LOW;
   HAL_GPIO_Init(GPIOC, &GPIO_InitStruct);

   /*Configure GPIO pins : Blauer_Taster_Pin Touch_Panel_Interrupt_Pin */
   GPIO_InitStruct.Pin = Blauer_Taster_Pin | Touch_Panel_Interrupt_Pin;
   GPIO_InitStruct.Mode = GPIO_MODE_IT_RISING;
   GPIO_InitStruct.Pull = GPIO_NOPULL;
   HAL_GPIO_Init(GPIOA, &GPIO_InitStruct);

   /*Configure GPIO pin : SCK_3_Pin */
   GPIO_InitStruct.Pin = SCK_3_Pin;
   GPIO_InitStruct.Mode = GPIO_MODE_OUTPUT_PP;
   GPIO_InitStruct.Pull = GPIO_NOPULL;
   GPIO_InitStruct.Speed = GPIO_SPEED_FREQ_LOW;
   HAL_GPIO_Init(SCK_3_GPIO_Port, &GPIO_InitStruct);

   /*Configure GPIO pin : PB2 */
   GPIO_InitStruct.Pin = GPIO_PIN_2;
   GPIO_InitStruct.Mode = GPIO_MODE_INPUT;
   GPIO_InitStruct.Pull = GPIO_NOPULL;
   HAL_GPIO_Init(GPIOB, &GPIO_InitStruct);

   /*Configure GPIO pins : PB12 PB14 PB15 */
   GPIO_InitStruct.Pin = GPIO_PIN_12 | GPIO_PIN_14 | GPIO_PIN_15;
   GPIO_InitStruct.Mode = GPIO_MODE_AF_PP;
   GPIO_InitStruct.Pull = GPIO_NOPULL;
   GPIO_InitStruct.Speed = GPIO_SPEED_FREQ_VERY_HIGH;
   GPIO_InitStruct.Alternate = GPIO_AF12_OTG_HS_FS;
   HAL_GPIO_Init(GPIOB, &GPIO_InitStruct);

   /*Configure GPIO pin : PB13 */
   GPIO_InitStruct.Pin = GPIO_PIN_13;
   GPIO_InitStruct.Mode = GPIO_MODE_INPUT;
   GPIO_InitStruct.Pull = GPIO_NOPULL;
   HAL_GPIO_Init(GPIOB, &GPIO_InitStruct);

   /*Configure GPIO pin : PD11 */
   GPIO_InitStruct.Pin = GPIO_PIN_11;
   GPIO_InitStruct.Mode = GPIO_MODE_INPUT;
   GPIO_InitStruct.Pull = GPIO_NOPULL;
   HAL_GPIO_Init(GPIOD, &GPIO_InitStruct);

   /*Configure GPIO pins : PD12 PD13 SCK_8_Pin */
   GPIO_InitStruct.Pin = GPIO_PIN_12 | GPIO_PIN_13 | SCK_8_Pin;
   GPIO_InitStruct.Mode = GPIO_MODE_OUTPUT_PP;
   GPIO_InitStruct.Pull = GPIO_NOPULL;
   GPIO_InitStruct.Speed = GPIO_SPEED_FREQ_LOW;
   HAL_GPIO_Init(GPIOD, &GPIO_InitStruct);

   /*Configure GPIO pins : SCK_5_Pin SCK_6_Pin LED_Green_Pin LED_Red_Pin */
   GPIO_InitStruct.Pin = SCK_5_Pin | SCK_6_Pin | LED_Green_Pin | LED_Red_Pin;
   GPIO_InitStruct.Mode = GPIO_MODE_OUTPUT_PP;
   GPIO_InitStruct.Pull = GPIO_NOPULL;
   GPIO_InitStruct.Speed = GPIO_SPEED_FREQ_LOW;
   HAL_GPIO_Init(GPIOG, &GPIO_InitStruct);

   /* EXTI interrupt init*/
   HAL_NVIC_SetPriority(EXTI0_IRQn, 4, 5);
   HAL_NVIC_EnableIRQ(EXTI0_IRQn);

   HAL_NVIC_SetPriority(EXTI2_IRQn, 2, 2);
   HAL_NVIC_EnableIRQ(EXTI2_IRQn);

   HAL_NVIC_SetPriority(EXTI3_IRQn, 2, 4);
   HAL_NVIC_EnableIRQ(EXTI3_IRQn);

   HAL_NVIC_SetPriority(EXTI4_IRQn, 5, 5);
   HAL_NVIC_EnableIRQ(EXTI4_IRQn);

   HAL_NVIC_SetPriority(EXTI15_10_IRQn, 3, 0);
   HAL_NVIC_EnableIRQ(EXTI15_10_IRQn);
}

/* USER CODE BEGIN 4 */
/*
 *******************************************************************************
 * GPIO Interrupt Callbackfunktionen
 *******************************************************************************
 */
void HAL_GPIO_EXTI_Callback(uint16_t GPIO_Pin) {
   uint8_t flag_input = 0;
   char flag[11];

   uint8_t busy_input = 0;
   char busy[11];

   /*
    * Interrupt blauer Taster (Level 4)
    * Der blaue Taster hat keine spezifische Funktion.
    * Er kann zum Debugen o.ä. eingesetzt werden.
    */
   if (GPIO_Pin == GPIO_PIN_0 && INIT_DONE) {
      at_lcd_seite(&LCD_Config);
      HAL_GPIO_TogglePin(GPIOG, GPIO_PIN_13);
   }

   /*
    * Interrupt IO Expander A FLAG (Level 2)
    * Flag: Signalisiert, dass einer der Schrittmotortreiber
    * einen Fehler signalisiert
    */
   if (GPIO_Pin == GPIO_PIN_2 && INIT_DONE) {
      /*
       * Warten bis spi pipe frei ist
       * Besser wäre hier: HAL_SPI_STATE_BUSY_TX_RX abfragen
       * Wartet man nicht, riskiert man ein falsches Ergebnis
       */
      HAL_Delay(10);

      flag_input = at_expander_readdata(ExpanderA, INTFA, 0x00);

     snprintf(flag, sizeof flag, BYTE_TO_BINARY_PATTERN,
               BYTE_TO_BINARY(flag_input));
      flag[8] = 'F';
      flag[9] = 0x00;

      /*
       * Damit der String sauber an den UART übergeben wird, wird CR NL und NULL
       * eingefügt
       */
      flag[9] = 0x0A;
      flag[10] = 0x0D;
      flag[11] = 0x00;
      TM_USART_Puts(USART1, flag);

      /* Busy zurücksetzen */
      at_expander_readdata(ExpanderA, INTCAPA, 0x00);
   }

   /*
    * Interrupt IO Expander B BUSY (Level 5)
    * Signalisiert ob Befehle noch abgearbeitet werden
    */
   if (GPIO_Pin == GPIO_PIN_3 && INIT_DONE) {
      /* Warten bis spi pipe frei ist */
      HAL_Delay(10);
      busy_input = at_expander_readdata(ExpanderB, INTFA, 0x00);

      // Abfrage ob input != 0 sonst nichts ausgeben
      snprintf(busy, sizeof busy, BYTE_TO_BINARY_PATTERN,
               BYTE_TO_BINARY(busy_input));
      busy[8] = 'B';
      busy[9] = 0x00;

      busy[9] = 0x0A;
      busy[10] = 0x0D;
      busy[11] = 0x00;
      TM_USART_Puts(USART1, busy);

      at_expander_readdata(ExpanderB, INTCAPA, 0x00);
   }

   /*
    * Interrupt USB Kabel eingesteckt (Level 5)
    * Für nähere Infos siehe Stromlaufplan
    * Bei eingestecktem USB Kabel PC --> 5V wird der Step-Down Konverter
    * deaktiviert
    */
   if (GPIO_Pin == GPIO_PIN_4 && INIT_DONE) {
      at_lcd_error();
   }

   /*
    * Interrupt Touchdisplay (Level 4)
    * Bei Tastendruck aktiv
    */
   if (GPIO_Pin == GPIO_PIN_15 && INIT_DONE) {
      at_lcd_state(&LCD_Config);
      /* touch detection delay register verhindert "prellen" --> wäre besser */
      ENTPRELL_DELAY;
      /* Setze Interrupt zurück */
      TM_I2C_Write(STMPE811_I2C, 0x82, 0x0B, 0x01);
   }
}
/*
 *******************************************************************************
 * UART Empfang Callbackfunktion
 *******************************************************************************
 */
void HAL_UART_RxCpltCallback(UART_HandleTypeDef* huart) {
   static uint8_t init = 1;
   static uint16_t len = 0;
   char UART_Buffer[MAX_BUFFER];

   /*
    * Initialisierungsvorgang mittels static Variable
    * Buffer initialisieren
    * Warten bis kein Müll mehr daherkommt... (zu Beginn wird irgendwas in den
    * Buffer geschrieben) deshalb die '~' abfrage
    */
   if (init == 1 || UART1_Data == '~') {
      UART1_Data = 0;
      memset(UART_Buffer, 0, MAX_BUFFER);
      init = 0;
   }

   /* Fülle Buffer mittels Callbackfunktion */
   if (huart->Instance == USART1) {
      /*
       * Eine UART Eingabe endet immer mit einem CR zumindest bei meinem PC
       * Solange kein Zeilenumbruch CR (0x0D) --> weiter Buffer befüllen
       */
      UART_Buffer[len] = UART1_Data;
      len++;
      /*
       * weil CR immer ein seltsames zeichen ausgibt und beim LCD Display
       * nicht gebraucht wird, ist die ausgabe hier dazwischen
       * Etwas verwirrend, weil Newline mit CR getausch wird
       */
      if (UART1_Data == 0x0D) {
         /* fuer die lcd ausgabe braucht man ein \n */
         UART_Buffer[len - 1] = 0x0A;
         UART_Buffer[len] = 0x00;

         at_lcd_debug(&UART_Buffer);

         /* fuer den parser --> nur darstellbare Zeichen */
         UART_Buffer[len - 1] = 0x00;
         at_uart_interpreter(&UART_Buffer);

#ifdef UART_DEBUG
         UART_Buffer[len - 1] = 0x0A;
         len++;
         UART_Buffer[len] = 0x0D;
         len++;
         UART_Buffer[len] = 0x00;

         HAL_UART_Transmit(&huart1, UART_Buffer, len, 1000);
#endif

         /* len und Buffer zurücksetzen */
         memset(UART_Buffer, 0, MAX_BUFFER);
         len = 0;
      }

      HAL_UART_Receive_IT(&huart1, &UART1_Data, sizeof(UART1_Data));
   }
}

/* USER CODE END 4 */

void _Error_Handler(char* file, int line) {
   /* USER CODE BEGIN Error_Handler_Debug */

   /* User can add his own implementation to report the HAL error return state
    */
   while (1) {
   }
   /* USER CODE END Error_Handler_Debug */
}

#ifdef USE_FULL_ASSERT

/**
 * @brief Reports the name of the source file and the source line number
 * where the assert_param error has occurred.
 * @param file: pointer to the source file name
 * @param line: assert_param error line source number
 * @retval None
 */
void assert_failed(uint8_t* file, uint32_t line) {
   /* USER CODE BEGIN 6 */
   /* User can add his own implementation to report the file name and line
    number,
    ex: printf("Wrong parameters value: file %s on line %d\r\n", file, line) */
   /* USER CODE END 6 */
}

#endif

/************************ (C) COPYRIGHT STMicroelectronics *****END OF FILE****/
